# RN831X_RN861X_MCU register map
File version: v0.0.1
CPU: RN831X_RN861X_MCU r1p0, little endian, MPU, no FPU
Registers are 32-bit, read-write, reset 0x0 unless marked. A register's access mark holds for its fields unless they carry their own. Offsets are from the block's base; [hi:lo] are bit positions; {n}, {i} and the like mark numbered series.

## SCU_CORE0 — SCU Module core0
Base 0x30018000
Same registers: SCU_CORE1 0xB0018000
0x00 WKEY access not given — Write Password Protection Register
  [31:0] WKEY — Password protection bits.
0x04 LCK access not given — LCK Control Register
  [31:0] LCK — SCU security attribute (08H~5CH) configuration lock register.
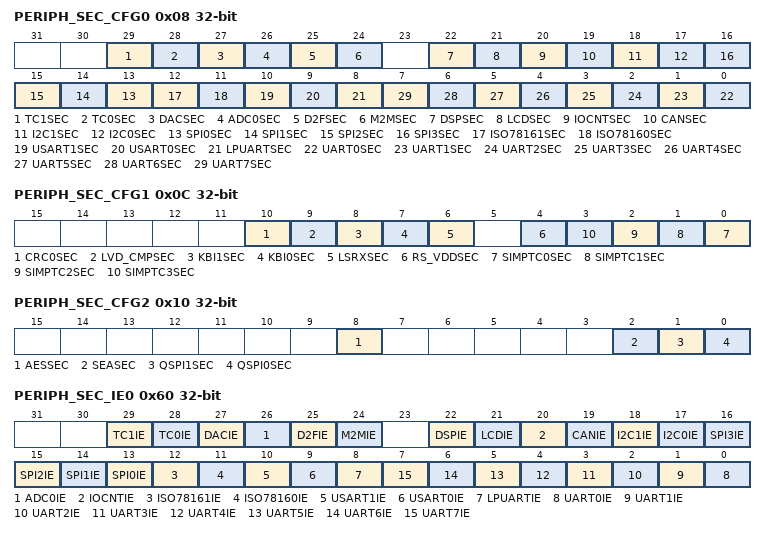
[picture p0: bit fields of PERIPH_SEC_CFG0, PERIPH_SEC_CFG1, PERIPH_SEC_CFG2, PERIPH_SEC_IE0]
0x08 PERIPH_SEC_CFG0 — Peripheral Security Configuration Register 0
  [29] TC1SEC — TC1 security attribute configuration
  [28] TC0SEC — TC0 security attribute configuration
  [27] DACSEC — DAC security attribute configuration
  [26] ADC0SEC — ADC0 security attribute configuration
  [25] D2FSEC — D2F security attribute configuration
  [24] M2MSEC — M2M security attribute configuration
  [22] DSPSEC — DSP security attribute configuration
  [21] LCDSEC — LCD security attribute configuration
  [20] IOCNTSEC — IOCNT security attribute configuration
  [19] CANSEC — CAN security attribute configuration
  [18] I2C1SEC — I2C1 security attribute configuration
  [17] I2C0SEC — I2C0 security attribute configuration
  [n+13] SPI{n}SEC (n=0..3) — SPI{n} security attribute configuration
  [12] ISO78161SEC — ISO7816-1 security attribute configuration
  [11] ISO78160SEC — ISO7816-0 security attribute configuration
  [10] USART1SEC — USART1 security attribute configuration
  [9] USART0SEC — USART0 security attribute configuration
  [8] LPUARTSEC — LPUART security attribute configuration
  [n] UART{n}SEC (n=0..7) — UART{n} security attribute configuration
0x0C PERIPH_SEC_CFG1 — Peripheral Security Configuration Register 1
  [10] CRC0SEC — CRC0 security attribute configuration
  [9] LVD_CMPSEC — LVD_CMP security attribute configuration
  [8] KBI1SEC — KBI1 security attribute configuration
  [7] KBI0SEC — KBI0 security attribute configuration
  [6] LSRXSEC — LSRX security attribute configuration
  [4] RS_VDDSEC — RS_VDD security attribute configuration
  [n] SIMPTC{n}SEC (n=0..3) — SIMP_TC{n} security attribute configuration
0x10 PERIPH_SEC_CFG2 — Peripheral Security Configuration Register 2
  [8] AESSEC — AES security attribute configuration
  [2] SEASEC — SEA security attribute configuration
  [1] QSPI1SEC — QSPI1 security attribute configuration
  [0] QSPI0SEC — QSPI0 security attribute configuration
0x1C GPIOA_SEC_CFG access not given — GPIOA Security Configuration Register
  [15:0] PA_SEC — Security attribute configuration for PA00~PA15
0x20 GPIOB_SEC_CFG access not given — GPIOB Security Configuration Register
  [15:0] PB_SEC — Security attribute configuration for PB00~PB15
0x24 GPIOC_SEC_CFG access not given — GPIOC Security Configuration Register
  [15:0] PC_SEC — Security attribute configuration for PC00~PC15
0x28 GPIOD_SEC_CFG access not given — GPIOD Security Configuration Register
  [15:0] PD_SEC — Security attribute configuration for PD00~PD15
0x2C GPIOE_SEC_CFG access not given — GPIOE Security Configuration Register
  [15:0] PE_SEC — Security attribute configuration for PE00~PE15
0x30 GPIOF_SEC_CFG access not given — GPIOF Security Configuration Register
  [15:0] PF_SEC — Security attribute configuration for PF00~PF15
0x34 GPIOG_SEC_CFG access not given — GPIOG Security Configuration Register
  [15:0] PG_SEC — Security attribute configuration for PG00~PG15
0x38 GPIOH_SEC_CFG access not given — GPIOH Security Configuration Register
  [1:0] PH_SEC — Security attribute configuration for PH00~PH01
0x5C SRAM_SEC_WM_CFG access not given — SRAM Security Watermark Configuration Register
  [3:0] SRAM_SEC_LEN — Secure SRAM region length configuration (1-4'ha)
0x60 PERIPH_SEC_IE0 — Peripheral Illegal Access Interrupt Enable Register 0
  [29] TC1IE — TC1 illegal access interrupt enable configuration
  [28] TC0IE — TC0 illegal access interrupt enable configuration
  [27] DACIE — DAC illegal access interrupt enable configuration
  [26] ADC0IE — ADC0 illegal access interrupt enable configuration
  [25] D2FIE — D2F illegal access interrupt enable configuration
  [24] M2MIE — M2M illegal access interrupt enable configuration
  [22] DSPIE — DSP illegal access interrupt enable configuration
  [21] LCDIE — LCD illegal access interrupt enable configuration
  [20] IOCNTIE — IOCNT illegal access interrupt enable configuration
  [19] CANIE — CAN illegal access interrupt enable configuration
  [18] I2C1IE — I2C1 illegal access interrupt enable configuration
  [17] I2C0IE — I2C0 illegal access interrupt enable configuration
  [n+13] SPI{n}IE (n=0..3) — SPI{n} illegal access interrupt enable configuration
  [12] ISO78161IE — ISO7816-1 illegal access interrupt enable configuration
  [11] ISO78160IE — ISO7816-0 illegal access interrupt enable configuration
  [10] USART1IE — USART1 illegal access interrupt enable configuration
  [9] USART0IE — USART0 illegal access interrupt enable configuration
  [8] LPUARTIE — LPUART illegal access interrupt enable configuration
  [n] UART{n}IE (n=0..7) — UART{n} illegal access interrupt enable configuration
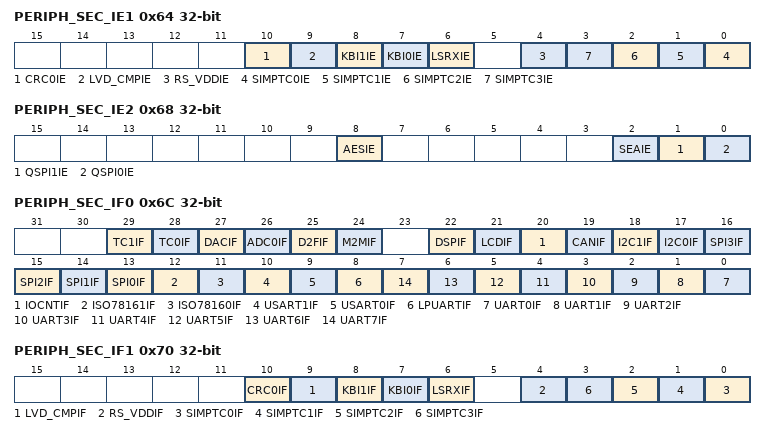
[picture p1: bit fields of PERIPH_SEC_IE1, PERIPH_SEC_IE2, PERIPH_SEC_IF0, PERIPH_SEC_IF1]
0x64 PERIPH_SEC_IE1 — Peripheral Illegal Access Interrupt Enable Register 1
  [10] CRC0IE — CRC0 illegal access interrupt enable configuration
  [9] LVD_CMPIE — LVD_CMP illegal access interrupt enable configuration
  [8] KBI1IE — KBI1 illegal access interrupt enable configuration
  [7] KBI0IE — KBI0 illegal access interrupt enable configuration
  [6] LSRXIE — LSRX illegal access interrupt enable configuration
  [4] RS_VDDIE — RS_VDD illegal access interrupt enable configuration
  [n] SIMPTC{n}IE (n=0..3) — SIMPTC{n} illegal access interrupt enable configuration
0x68 PERIPH_SEC_IE2 — Peripheral Illegal Access Interrupt Enable Register 2
  [8] AESIE — AES illegal access interrupt enable configuration
  [2] SEAIE — SEA illegal access interrupt enable configuration
  [1] QSPI1IE — QSPI1 illegal access interrupt enable configuration
  [0] QSPI0IE — QSPI0 illegal access interrupt enable configuration
0x6C PERIPH_SEC_IF0 — Peripheral Illegal Access Interrupt Flag Register 0
  [29] TC1IF — TC1 illegal access interrupt flag bit
  [28] TC0IF — TC0 illegal access interrupt flag bit
  [27] DACIF — DAC illegal access interrupt flag bit
  [26] ADC0IF — ADC0 illegal access interrupt flag bit
  [25] D2FIF — D2F illegal access interrupt flag bit
  [24] M2MIF — M2M illegal access interrupt flag bit
  [22] DSPIF — DSP illegal access interrupt flag bit
  [21] LCDIF — LCD illegal access interrupt flag bit
  [20] IOCNTIF — IOCNT illegal access interrupt flag bit
  [19] CANIF — CAN illegal access interrupt flag bit
  [18] I2C1IF — I2C1 illegal access interrupt flag bit
  [17] I2C0IF — I2C0 illegal access interrupt flag bit
  [n+13] SPI{n}IF (n=0..3) — SPI{n} illegal access interrupt flag bit
  [12] ISO78161IF — ISO7816-1 illegal access interrupt flag bit
  [11] ISO78160IF — ISO7816-0 illegal access interrupt flag bit
  [10] USART1IF — USART1 illegal access interrupt flag bit
  [9] USART0IF — USART0 illegal access interrupt flag bit
  [8] LPUARTIF — LPUART illegal access interrupt flag bit
  [n] UART{n}IF (n=0..7) — UART{n} illegal access interrupt flag bit
0x70 PERIPH_SEC_IF1 — Peripheral Illegal Access Interrupt Flag Register 1
  [10] CRC0IF — CRC0 illegal access interrupt flag bit
  [9] LVD_CMPIF — LVD_CMP illegal access interrupt flag bit
  [8] KBI1IF — KBI1 illegal access interrupt flag bit
  [7] KBI0IF — KBI0 illegal access interrupt flag bit
  [6] LSRXIF — LSRX illegal access interrupt flag bit
  [4] RS_VDDIF — RS_VDD illegal access interrupt flag bit
  [n] SIMPTC{n}IF (n=0..3) — SIMPTC{n} illegal access interrupt flag bit
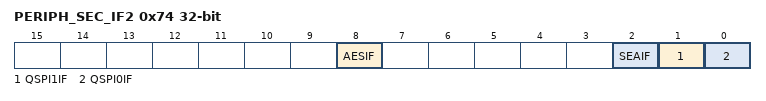
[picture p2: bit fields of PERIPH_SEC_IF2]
0x74 PERIPH_SEC_IF2 — Peripheral Illegal Access Interrupt Flag Register 2
  [8] AESIF — AES illegal access interrupt flag bit
  [2] SEAIF — SEA illegal access interrupt flag bit
  [1] QSPI1IF — QSPI1 illegal access interrupt flag bit
  [0] QSPI0IF — QSPI0 illegal access interrupt flag bit
